# MKL28Z7 register map
Vendor: Freescale Semiconductor, Inc.; Series: Kinetis_L; File version: 1.6
CPU: CM0PLUS r0p0, little endian, no MPU, no FPU, VTOR, 2 interrupt priority bits
Registers are 32-bit, read-write, reset 0x0 unless marked. A register's access mark holds for its fields unless they carry their own. Offsets are from the block's base; [hi:lo] are bit positions; {n}, {i} and the like mark numbered series; 'fields as' and 'values as' point back to an identical list.

## LPTMR0 — Low Power Timer
Base 0x40034000; register names take the prefix LPTMR0_
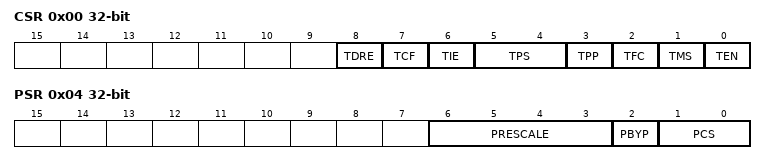
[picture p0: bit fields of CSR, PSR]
0x00 CSR — Low Power Timer Control Status Register
  [8] TDRE — Timer DMA Request Enable
    0=Timer DMA Request disabled; 1=Timer DMA Request enabled
  [7] TCF — Timer Compare Flag
    0=The value of CNR is not equal to CMR and increments; 1=The value of CNR is equal to CMR and increments
  [6] TIE — Timer Interrupt Enable
    0=Timer interrupt disabled; 1=Timer interrupt enabled
  [5:4] TPS — Timer Pin Select
    {v}=Pulse counter input {v} is selected (v=0..3)
  [3] TPP — Timer Pin Polarity
    0=Pulse Counter input source is active-high, and the CNR will increment on the rising-edge; 1=Pulse Counter input source is active-low, and the CNR will increment on the falling-edge
  [2] TFC — Timer Free-Running Counter
    0=CNR is reset whenever TCF is set; 1=CNR is reset on overflow
  [1] TMS — Timer Mode Select
    0=Time Counter mode; 1=Pulse Counter mode
  [0] TEN — Timer Enable
    0=LPTMR is disabled and internal logic is reset; 1=LPTMR is enabled
0x04 PSR — Low Power Timer Prescale Register
  [6:3] PRESCALE — Prescale Value
    0=Prescaler divides the prescaler clock by 2; glitch filter does not support this configuration; 1=Prescaler divides the prescaler clock by 4; glitch filter recognizes change on input pin after 2 rising clock edges; 2=Prescaler divides the prescaler clock by 8; glitch filter recognizes change on input pin after 4 rising clock edges; 3=Prescaler divides the prescaler clock by 16; glitch filter recognizes change on input pin after 8 rising clock edges; 4=Prescaler divides the prescaler clock by 32; glitch filter recognizes change on input pin after 16 rising clock edges; 5=Prescaler divides the prescaler clock by 64; glitch filter recognizes change on input pin after 32 rising clock edges; 6=Prescaler divides the prescaler clock by 128; glitch filter recognizes change on input pin after 64 rising clock edges; 7=Prescaler divides the prescaler clock by 256; glitch filter recognizes change on input pin after 128 rising clock edges; 8=Prescaler divides the prescaler clock by 512; glitch filter recognizes change on input pin after 256 rising clock edges; 9=Prescaler divides the prescaler clock by 1024; glitch filter recognizes change on input pin after 512 rising clock edges; 10=Prescaler divides the prescaler clock by 2048; glitch filter recognizes change on input pin after 1024 rising clock edges; 11=Prescaler divides the prescaler clock by 4096; glitch filter recognizes change on input pin after 2048 rising clock edges; 12=Prescaler divides the prescaler clock by 8192; glitch filter recognizes change on input pin after 4096 rising clock edges; 13=Prescaler divides the prescaler clock by 16,384; glitch filter recognizes change on input pin after 8192 rising clock edges; 14=Prescaler divides the prescaler clock by 32,768; glitch filter recognizes change on input pin after 16,384 rising clock edges; 15=Prescaler divides the prescaler clock by 65,536; glitch filter recognizes change on input pin after 32,768 rising clock edges
  [2] PBYP — Prescaler Bypass
    0=Prescaler/glitch filter is enabled; 1=Prescaler/glitch filter is bypassed
  [1:0] PCS — Prescaler Clock Select
    {v}=Prescaler/glitch filter clock {v} selected (v=0..3)
0x08 CMR — Low Power Timer Compare Register
  [15:0] COMPARE — Compare Value
0x0C CNR — Low Power Timer Counter Register
  [15:0] COUNTER — Counter Value

## LPTMR1 — Low Power Timer
Base 0x400B5000; register names take the prefix LPTMR1_
Registers as LPTMR0.

## LLWU0 — Low leakage wakeup unit
Base 0x40061000; register names take the prefix LLWU0_
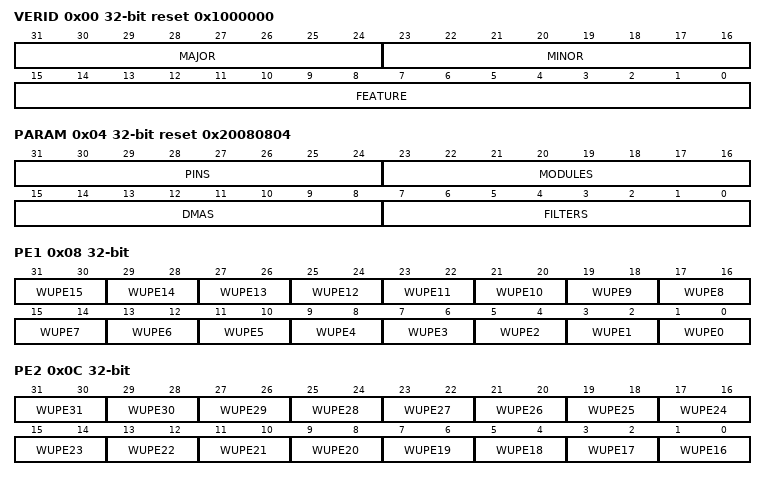
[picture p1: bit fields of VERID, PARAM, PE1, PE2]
0x00 VERID ro reset 0x1000000 — Version ID Register
  [31:24] MAJOR — Major Version Number
  [23:16] MINOR — Minor Version Number
  [15:0] FEATURE — Feature Specification Number
    0=Standard features implemented
0x04 PARAM ro reset 0x20080804 — Parameter Register
  [31:24] PINS — Pin Number
  [23:16] MODULES — Module Number
  [15:8] DMAS — DMA Number
  [7:0] FILTERS — Filter Number
0x08 PE1 — LLWU Pin Enable 1 register
  [all] fields
    0=External input pin disabled as wakeup input; 1=External input pin enabled with rising edge detection; 2=External input pin enabled with falling edge detection; 3=External input pin enabled with any change detection
  [2n+1:2n] WUPE{n} (n=0..15) — Wakeup Pin Enable For LLWU_P{n}
0x0C PE2 — LLWU Pin Enable 2 register
  [all] fields
    values as the fields of PE1
  [2n-31:2n-32] WUPE{n} (n=16..31) — Wakeup Pin Enable For LLWU_P{n}
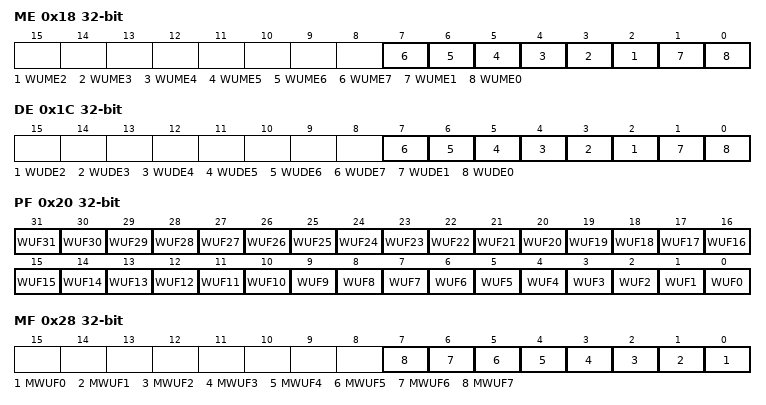
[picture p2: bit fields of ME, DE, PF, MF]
0x18 ME — LLWU Module Interrupt Enable register
  [all] fields
    0=Internal module flag not used as wakeup source; 1=Internal module flag used as wakeup source
  [n] WUME{n} (n=2..7) — Wakeup Module Enable For Module {n}
  [1] WUME1 — Wakeup Module Enable for Module 1
  [0] WUME0 — Wakeup Module Enable For Module 0
0x1C DE — LLWU Module DMA Enable register
  [all] fields
    0=Internal module request not used as a DMA wakeup source; 1=Internal module request used as a DMA wakeup source
  [n] WUDE{n} (n=2..7) — DMA Wakeup Enable For Module {n}
  [1] WUDE1 — DMA Wakeup Enable for Module 1
  [0] WUDE0 — DMA Wakeup Enable For Module 0
0x20 PF — LLWU Pin Flag register
  [n] WUF{n} (n=0..31) — Wakeup Flag For LLWU_P{n}
    0=LLWU_P{n} input was not a wakeup source; 1=LLWU_P{n} input was a wakeup source
0x28 MF ro — LLWU Module Interrupt Flag register
  [n] MWUF{n} (n=0..7) — Wakeup flag For module {n}
    0=Module {n} input was not a wakeup source; 1=Module {n} input was a wakeup source
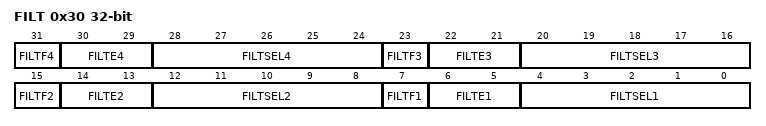
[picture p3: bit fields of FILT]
0x30 FILT — LLWU Pin Filter register
  [8n-1] FILTF{n} (n=1..4) — Filter {n} Flag
    0=Pin Filter 1 was not a wakeup source; 1=Pin Filter 1 was a wakeup source
  [8n-2:8n-3] FILTE{n} (n=1..4) — Filter {n} Enable
    0=Filter disabled; 1=Filter posedge detect enabled; 2=Filter negedge detect enabled; 3=Filter any edge detect enabled
  [8n-4:8n-8] FILTSEL{n} (n=1..4) — Filter {n} Pin Select
    0=Select LLWU_P0 for filter; 31=Select LLWU_P31 for filter
